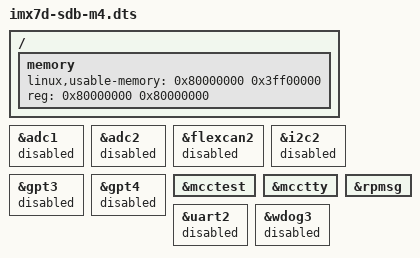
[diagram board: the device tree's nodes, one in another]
/*
 * Copyright (C) 2015 Freescale Semiconductor, Inc.
 *
 * This program is free software; you can redistribute it and/or modify
 * it under the terms of the GNU General Public License version 2 as
 * published by the Free Software Foundation.
 */

#include "imx7d-sdb.dts"

/ {
	memory {
		linux,usable-memory = <0x80000000 0x3ff00000>;
		reg = <0x80000000 0x80000000>;
	};
};

&adc1 {
	status = "disabled";
};

&adc2 {
	status = "disabled";
};

&flexcan2 {
	status = "disabled";
};

&i2c2 {
	status = "disabled";
};

&gpt3 {
	status = "disabled";
};

&gpt4 {
	status = "disabled";
};

&mcctest{
	status = "okay";
};

&mcctty{
	status = "okay";
};

&rpmsg{
	status = "okay";
};

&uart2 {
	status = "disabled";
};

&wdog3{
	status = "disabled";
};
